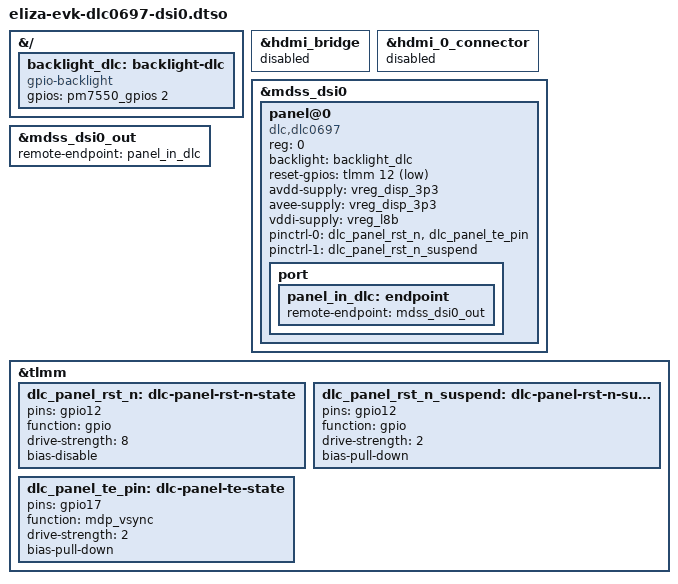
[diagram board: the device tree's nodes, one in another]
// SPDX-License-Identifier: BSD-3-Clause
/*
 * Copyright (c) Qualcomm Technologies, Inc. and/or its subsidiaries.
 */

/dts-v1/;
/plugin/;

#include <dt-bindings/gpio/gpio.h>

&{/} {
	backlight_dlc: backlight-dlc {
		compatible = "gpio-backlight";
		gpios = <&pm7550_gpios 2 GPIO_ACTIVE_HIGH>;
	};
};

&hdmi_bridge {
	status = "disabled";
};

&hdmi_0_connector {
	status = "disabled";
};

&mdss_dsi0 {
	#address-cells = <1>;
	#size-cells = <0>;

	panel@0 {
		compatible = "dlc,dlc0697", "ilitek,ili7807s";
		reg = <0>;
		backlight = <&backlight_dlc>;
		reset-gpios = <&tlmm 12 GPIO_ACTIVE_LOW>;
		avdd-supply = <&vreg_disp_3p3>;
		avee-supply = <&vreg_disp_3p3>;
		vddi-supply = <&vreg_l8b>;
		pinctrl-0 = <&dlc_panel_rst_n>, <&dlc_panel_te_pin>;
		pinctrl-1 = <&dlc_panel_rst_n_suspend>;
		pinctrl-names = "default", "sleep";

		port {
			panel_in_dlc: endpoint {
				remote-endpoint = <&mdss_dsi0_out>;
			};
		};
	};
};

&mdss_dsi0_out {
	remote-endpoint = <&panel_in_dlc>;
};

&tlmm {
	dlc_panel_rst_n: dlc-panel-rst-n-state {
		pins = "gpio12";
		function = "gpio";
		drive-strength = <8>;
		bias-disable;
	};

	dlc_panel_rst_n_suspend: dlc-panel-rst-n-suspend-state {
		pins = "gpio12";
		function = "gpio";
		drive-strength = <2>;
		bias-pull-down;
	};

	dlc_panel_te_pin: dlc-panel-te-state {
		pins = "gpio17";
		function = "mdp_vsync";
		drive-strength = <2>;
		bias-pull-down;
	};
};
